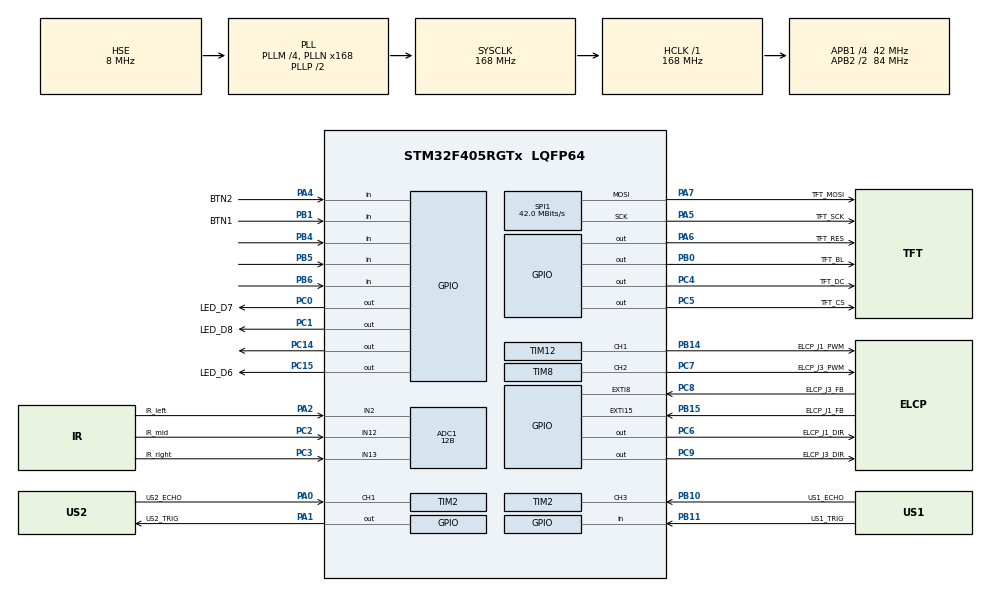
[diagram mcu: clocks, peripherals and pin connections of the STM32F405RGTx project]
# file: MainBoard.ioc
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ADC1.Channel-0\#ChannelRegularConversion=ADC_CHANNEL_2
ADC1.ClockPrescaler=ADC_CLOCK_SYNC_PCLK_DIV4
ADC1.ContinuousConvMode=DISABLE
ADC1.DMAContinuousRequests=DISABLE
ADC1.DataAlign=ADC_DATAALIGN_RIGHT
ADC1.DiscontinuousConvMode=DISABLE
ADC1.EOCSelection=ADC_EOC_SINGLE_CONV
ADC1.EnableAnalogWatchDog=false
ADC1.ExternalTrigConv=ADC_SOFTWARE_START
ADC1.ExternalTrigConvEdge=ADC_EXTERNALTRIGCONVEDGE_NONE
ADC1.InjNumberOfConversion=1
ADC1.NbrOfConversion=1
ADC1.NbrOfConversionFlag=1
ADC1.Rank-0\#ChannelRegularConversion=1
ADC1.Resolution=ADC_RESOLUTION_12B
ADC1.SamplingTime-0\#ChannelRegularConversion=ADC_SAMPLETIME_84CYCLES
ADC1.ScanConvMode=DISABLE
ADC1.master=1
Dma.Request0=SPI1_TX
Dma.SPI1_TX.0.Direction=DMA_MEMORY_TO_PERIPH
Dma.SPI1_TX.0.FIFOMode=DMA_FIFOMODE_ENABLE
Dma.SPI1_TX.0.FIFOThreshold=DMA_FIFO_THRESHOLD_FULL
Dma.SPI1_TX.0.Instance=DMA2_Stream3
Dma.SPI1_TX.0.MemBurst=DMA_MBURST_INC16
Dma.SPI1_TX.0.MemDataAlignment=DMA_MDATAALIGN_BYTE
Dma.SPI1_TX.0.MemInc=DMA_MINC_ENABLE
Dma.SPI1_TX.0.Mode=DMA_NORMAL
Dma.SPI1_TX.0.PeriphBurst=DMA_PBURST_SINGLE
Dma.SPI1_TX.0.PeriphDataAlignment=DMA_PDATAALIGN_BYTE
Dma.SPI1_TX.0.PeriphInc=DMA_PINC_DISABLE
Dma.SPI1_TX.0.Priority=DMA_PRIORITY_LOW
Mcu.Family=STM32F4
Mcu.Name=STM32F405RGTx
Mcu.Package=LQFP64
NVIC.DMA2_Stream3_IRQn=true\:0\:0\:false\:false\:true\:false\:true\:true
NVIC.EXTI15_10_IRQn=true\:0\:0\:false\:false\:true\:true\:true\:true
NVIC.EXTI9_5_IRQn=true\:0\:0\:false\:false\:true\:true\:true\:true
NVIC.PriorityGroup=NVIC_PRIORITYGROUP_4
NVIC.SPI1_IRQn=true\:0\:0\:false\:false\:true\:true\:true\:true
NVIC.TIM2_IRQn=true\:0\:0\:false\:false\:true\:true\:true\:true
PA0-WKUP.GPIO_Label=US2_ECHO
PA0-WKUP.Signal=S_TIM2_CH1_ETR
PA1.GPIO_Label=US2_TRIG
PA1.Signal=GPIO_Output
PA13.Mode=Serial_Wire
PA13.Signal=SYS_JTMS-SWDIO
PA14.Mode=Serial_Wire
PA14.Signal=SYS_JTCK-SWCLK
PA2.GPIO_Label=IR_left
PA2.Signal=ADCx_IN2
PA4.GPIO_Label=BTN2
PA4.GPIO_PuPd=GPIO_PULLUP
PA4.Signal=GPIO_Input
PA5.GPIO_Label=TFT_SCK
PA5.Mode=TX_Only_Simplex_Unidirect_Master
PA5.Signal=SPI1_SCK
PA6.GPIO_Label=TFT_RES
PA6.Signal=GPIO_Output
PA7.GPIO_Label=TFT_MOSI
PA7.Mode=TX_Only_Simplex_Unidirect_Master
PA7.Signal=SPI1_MOSI
PB0.GPIO_Label=TFT_BL
PB0.Signal=GPIO_Output
PB1.GPIO_Label=BTN1
PB1.GPIO_PuPd=GPIO_PULLUP
PB1.Signal=GPIO_Input
PB10.GPIO_Label=US1_ECHO
PB10.Signal=S_TIM2_CH3
PB11.GPIO_Label=US1_TRIG
PB11.Signal=GPIO_Input
PB14.GPIO_Label=ELCP_J1_PWM
PB14.Signal=S_TIM12_CH1
PB15.GPIO_Label=ELCP_J1_FB
PB15.GPIO_PuPd=GPIO_PULLUP
PB15.Signal=GPXTI15
PB4.Signal=GPIO_Input
PB5.Signal=GPIO_Input
PB6.Signal=GPIO_Input
PC0.GPIO_Label=LED_D7
PC0.PinState=GPIO_PIN_SET
PC0.Signal=GPIO_Output
PC1.GPIO_Label=LED_D8
PC1.PinState=GPIO_PIN_SET
PC1.Signal=GPIO_Output
PC14-OSC32_IN.Signal=GPIO_Output
PC15-OSC32_OUT.GPIO_Label=LED_D6
PC15-OSC32_OUT.PinState=GPIO_PIN_SET
PC15-OSC32_OUT.Signal=GPIO_Output
PC2.GPIO_Label=IR_mid
PC2.Signal=ADCx_IN12
PC3.GPIO_Label=IR_right
PC3.Signal=ADCx_IN13
PC4.GPIO_Label=TFT_DC
PC4.Signal=GPIO_Output
PC5.GPIO_Label=TFT_CS
PC5.Signal=GPIO_Output
PC6.GPIO_Label=ELCP_J1_DIR
PC6.GPIO_ModeDefaultOutputPP=GPIO_MODE_OUTPUT_OD
PC6.GPIO_PuPd=GPIO_NOPULL
PC6.Signal=GPIO_Output
PC7.GPIO_Label=ELCP_J3_PWM
PC7.Signal=S_TIM8_CH2
PC8.GPIO_Label=ELCP_J3_FB
PC8.GPIO_PuPd=GPIO_PULLUP
PC8.Signal=GPXTI8
PC9.GPIO_Label=ELCP_J3_DIR
PC9.GPIO_ModeDefaultOutputPP=GPIO_MODE_OUTPUT_OD
PC9.GPIO_PuPd=GPIO_NOPULL
PC9.Signal=GPIO_Output
PH0-OSC_IN.Mode=HSE-External-Oscillator
PH0-OSC_IN.Signal=RCC_OSC_IN
PH1-OSC_OUT.Mode=HSE-External-Oscillator
PH1-OSC_OUT.Signal=RCC_OSC_OUT
ProjectManager.HeapSize=0x200
ProjectManager.StackSize=0x400
ProjectManager.TargetToolchain=CMake
RCC.48MHZClocksFreq_Value=84000000
RCC.AHBFreq_Value=168000000
RCC.APB1CLKDivider=RCC_HCLK_DIV4
RCC.APB1Freq_Value=42000000
RCC.APB1TimFreq_Value=84000000
RCC.APB2CLKDivider=RCC_HCLK_DIV2
RCC.APB2Freq_Value=84000000
RCC.APB2TimFreq_Value=168000000
RCC.CortexFreq_Value=168000000
RCC.HCLKFreq_Value=168000000
RCC.HSE_VALUE=8000000
RCC.HSI_VALUE=16000000
RCC.LSE_VALUE=32768
RCC.PLLM=4
RCC.PLLN=168
RCC.PLLSourceVirtual=RCC_PLLSOURCE_HSE
RCC.SYSCLKFreq_VALUE=168000000
RCC.SYSCLKSource=RCC_SYSCLKSOURCE_PLLCLK
RCC.VCOOutputFreq_Value=336000000
SH.ADCx_IN12.0=ADC1_IN12,IN12
SH.ADCx_IN13.0=ADC1_IN13,IN13
SH.ADCx_IN2.0=ADC1_IN2,IN2
SH.S_TIM12_CH1.0=TIM12_CH1,PWM Generation1 CH1
SH.S_TIM2_CH1_ETR.0=TIM2_CH1,Input_Capture1_from_TI1
SH.S_TIM2_CH3.0=TIM2_CH3,Input_Capture3_from_TI3
SH.S_TIM8_CH2.0=TIM8_CH2,PWM Generation2 CH2
SPI1.BaudRatePrescaler=SPI_BAUDRATEPRESCALER_2
SPI1.CalculateBaudRate=42.0 MBits/s
SPI1.Direction=SPI_DIRECTION_2LINES
SPI1.Mode=SPI_MODE_MASTER
SPI1.VirtualType=VM_MASTER
TIM12.AutoReloadPreload=TIM_AUTORELOAD_PRELOAD_ENABLE
TIM12.Channel-PWM\ Generation1\ CH1=TIM_CHANNEL_1
TIM12.Period=1049
TIM12.Prescaler=7
TIM2.Channel-Input_Capture1_from_TI1=TIM_CHANNEL_1
TIM2.Channel-Input_Capture3_from_TI3=TIM_CHANNEL_3
TIM2.Period=4294967295
TIM2.Prescaler=83
TIM8.AutoReloadPreload=TIM_AUTORELOAD_PRELOAD_ENABLE
TIM8.Channel-PWM\ Generation2\ CH2=TIM_CHANNEL_2
TIM8.OCPolarity_2=TIM_OCPOLARITY_HIGH
TIM8.Period=1049
TIM8.Prescaler=7
VP_TIM2_VS_ClockSourceINT.Mode=Internal
VP_TIM3_VS_ClockSourceINT.Mode=Internal
VP_TIM8_VS_ClockSourceINT.Mode=Internal
board=custom

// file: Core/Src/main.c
/* USER CODE BEGIN Header */
/**
  ******************************************************************************
  * @file           : main.c
  * @brief          : Main program body
  ******************************************************************************
  * @attention
  *
  * Copyright (c) 2026 STMicroelectronics.
  * All rights reserved.
  *
  * This software is licensed under terms that can be found in the LICENSE file
  * in the root directory of this software component.
  * If no LICENSE file comes with this software, it is provided AS-IS.
  *
  ******************************************************************************
  */
/* USER CODE END Header */
#include "main.h"
#include "adc.h"
#include "dma.h"
#include "spi.h"
#include "tim.h"
#include "gpio.h"

/* USER CODE BEGIN Includes */
#include "lcd/lcd.h"
#include "lcd/lcd_graphics.h"
#include "robotics_logo.h"
#include "elcp_motor/elcp_motor.h"
#include "encoder_calibration.h"
#include "ar_merged_app.h"
/* USER CODE END Includes */

void SystemClock_Config(void);

int main(void)
{

  /* MCU Configuration--------------------------------------------------------*/

  /* Reset of all peripherals, Initializes the Flash interface and the Systick. */
  HAL_Init();

  /* Configure the system clock */
  SystemClock_Config();

  /* Initialize all configured peripherals */
  MX_GPIO_Init();
  MX_DMA_Init();
  MX_ADC1_Init();
  MX_SPI1_Init();
  MX_TIM2_Init();
  MX_TIM8_Init();
  MX_TIM12_Init();
  MX_TIM3_Init();
  /* USER CODE BEGIN 2 */
  /* Active navigation is button-started; disconnect motor power during
     setup. Software zero PWM is not an independent power cutoff. */
  tft_init(PIN_ON_TOP, BLACK, WHITE, CYAN, DARK_GREY);
  tft_update(0);
  AR_MergedApp_Init();

  /* USER CODE END 2 */

  /* Infinite loop */
  while (1)
  {

    /* USER CODE BEGIN 3 */
    AR_MergedApp_Update();
  }
  /* USER CODE END 3 */
}

void SystemClock_Config(void)
{
  RCC_OscInitTypeDef RCC_OscInitStruct = {0};
  RCC_ClkInitTypeDef RCC_ClkInitStruct = {0};

  /** Configure the main internal regulator output voltage
  */
  __HAL_RCC_PWR_CLK_ENABLE();
  __HAL_PWR_VOLTAGESCALING_CONFIG(PWR_REGULATOR_VOLTAGE_SCALE1);

  /** Initializes the RCC Oscillators according to the specified parameters
  * in the RCC_OscInitTypeDef structure.
  */
  RCC_OscInitStruct.OscillatorType = RCC_OSCILLATORTYPE_HSE;
  RCC_OscInitStruct.HSEState = RCC_HSE_ON;
  RCC_OscInitStruct.PLL.PLLState = RCC_PLL_ON;
  RCC_OscInitStruct.PLL.PLLSource = RCC_PLLSOURCE_HSE;
  RCC_OscInitStruct.PLL.PLLM = 4;
  RCC_OscInitStruct.PLL.PLLN = 168;
  RCC_OscInitStruct.PLL.PLLP = RCC_PLLP_DIV2;
  RCC_OscInitStruct.PLL.PLLQ = 4;
  if (HAL_RCC_OscConfig(&RCC_OscInitStruct) != HAL_OK)
  {
    Error_Handler();
  }

  /** Initializes the CPU, AHB and APB buses clocks
  */
  RCC_ClkInitStruct.ClockType = RCC_CLOCKTYPE_HCLK|RCC_CLOCKTYPE_SYSCLK
                              |RCC_CLOCKTYPE_PCLK1|RCC_CLOCKTYPE_PCLK2;
  RCC_ClkInitStruct.SYSCLKSource = RCC_SYSCLKSOURCE_PLLCLK;
  RCC_ClkInitStruct.AHBCLKDivider = RCC_SYSCLK_DIV1;
  RCC_ClkInitStruct.APB1CLKDivider = RCC_HCLK_DIV4;
  RCC_ClkInitStruct.APB2CLKDivider = RCC_HCLK_DIV2;

  if (HAL_RCC_ClockConfig(&RCC_ClkInitStruct, FLASH_LATENCY_5) != HAL_OK)
  {
    Error_Handler();
  }
}

void Error_Handler(void)
{
  __disable_irq();
  while (1)
  {
  }
}
